# f29h85x_hsm_ctrl_regs register map
Vendor: Texas Instruments
Peripheral module from a debugger description file (folder HSM).
Registers are 32-bit, read-write, no defined reset value unless marked. A register's access mark holds for its fields unless they carry their own. Offsets are as the file gives them; lines under a group give offsets from that group; [hi:lo] are bit positions; {n}, {i} and the like mark numbered series; 'fields as' and 'values as' point back to an identical list; <NAME> marks a mode.

## HSM_CTRL — HSM CTRL Registers
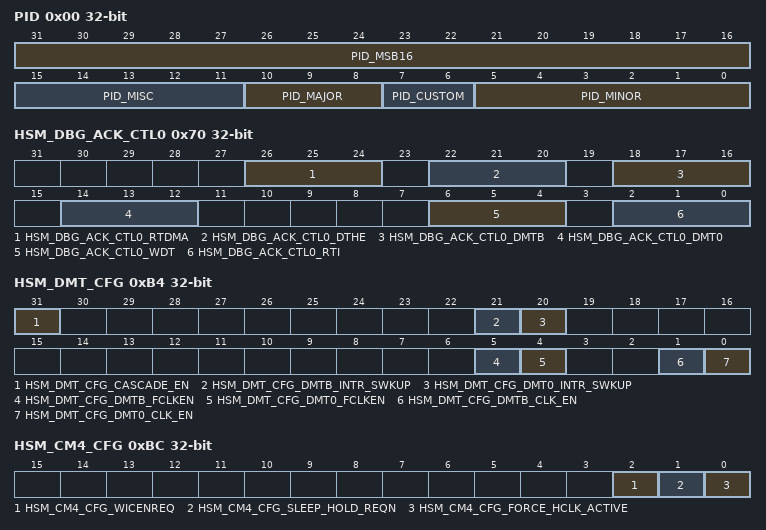
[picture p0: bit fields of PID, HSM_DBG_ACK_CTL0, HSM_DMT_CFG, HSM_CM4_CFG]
0x00 PID ro
  [31:16] PID_MSB16, [15:11] PID_MISC, [10:8] PID_MAJOR, [7:6] PID_CUSTOM, [5:0] PID_MINOR
{0x4+4i} HW_REG{i} (i=0..3)
  [31:0] HW_REG{i}_HWREG{i}
0x14 HSM_B0_MEMINIT_START
  [0] HSM_B0_MEMINIT_START_HSM_B0_MEMINIT_START
0x18 HSM_B0_MEMINIT_STATUS ro
  [0] HSM_B0_MEMINIT_STATUS_HSM_B0_MEMINIT_STATUS
0x1C HSM_B0_MEMINIT_DONE
  [0] HSM_B0_MEMINIT_DONE_HSM_B0_MEMINIT_DONE
0x20 HSM_B1_MEMINIT_START
  [0] HSM_B1_MEMINIT_START_HSM_B1_MEMINIT_START
0x24 HSM_B1_MEMINIT_STATUS ro
  [0] HSM_B1_MEMINIT_STATUS_HSM_B1_MEMINIT_STATUS
0x28 HSM_B1_MEMINIT_DONE
  [0] HSM_B1_MEMINIT_DONE_HSM_B1_MEMINIT_DONE
0x44 HSM_SECURERAM_MEMINIT_START
  [0] HSM_SECURERAM_MEMINIT_START_HSM_SECURE_MEMINIT_START
0x48 HSM_SECURERAM_MEMINIT_STATUS ro
  [0] HSM_SECURERAM_MEMINIT_STATUS_HSM_SECURE_MEMINIT_STATUS
0x4C HSM_SECURERAM_MEMINIT_DONE
  [0] HSM_SECURERAM_MEMINIT_DONE_HSM_SECURE_MEMINIT_DONE
0x70 HSM_DBG_ACK_CTL0
  [26:24] HSM_DBG_ACK_CTL0_RTDMA, [22:20] HSM_DBG_ACK_CTL0_DTHE, [18:16] HSM_DBG_ACK_CTL0_DMTB, [14:12] HSM_DBG_ACK_CTL0_DMT0, [6:4] HSM_DBG_ACK_CTL0_WDT, [2:0] HSM_DBG_ACK_CTL0_RTI
0x74 HSM_CM4_POR_RST_CTRL — Reserved. Not supported in this version of HW
  [2:0] HSM_CM4_POR_RST_CTRL_ASSERT
0x78 HSM_CM4_SYS_RST_CTRL — Reserved. Not supported in this version of HW
  [2:0] HSM_CM4_SYS_RST_CTRL_ASSERT
0x7C HSM_RTC_RST_CTRL — Reset control for RTC. Reset on PORESETn only
  [2:0] HSM_RTC_RST_CTRL_ASSERT
0x80 HSM_RTI0_RST_CTRL
  [2:0] HSM_RTI0_RST_CTRL_ASSERT
0x84 HSM_WDT_RST_CTRL
  [2:0] HSM_WDT_RST_CTRL_ASSERT
0x88 HSM_DCCA_RST_CTRL
  [2:0] HSM_DCCA_RST_CTRL_ASSERT
0x8C HSM_ESM_RST_CTRL
  [2:0] HSM_ESM_RST_CTRL_ASSERT
0x90 HSM_DMT0_RST_CTRL
  [2:0] HSM_DMT0_RST_CTRL_ASSERT
0x94 HSM_DMT1_RST_CTRL
  [2:0] HSM_DMT1_RST_CTRL_ASSERT
0x98 HSM_DMA_RST_CTRL
  [2:0] HSM_DMA_RST_CTRL_ASSERT
0x9C HSM_INFRA_RST_CTRL
  [2:0] HSM_INFRA_RST_CTRL_ASSERT
0xA0 HSM_DTHE_RST_CTRL
  [2:0] HSM_DTHE_RST_CTRL_ASSERT
0xA4 HSM_SHA_RST_CTRL
  [2:0] HSM_SHA_RST_CTRL_ASSERT
0xA8 HSM_TRNG_RST_CTRL
  [2:0] HSM_TRNG_RST_CTRL_ASSERT
0xAC HSM_PKE4P2_RST_CTRL
  [2:0] HSM_PKE4P2_RST_CTRL_ASSERT
0xB0 HSM_AES_RST_CTRL
  [2:0] HSM_AES_RST_CTRL_ASSERT
0xB4 HSM_DMT_CFG
  [31] HSM_DMT_CFG_CASCADE_EN, [21] HSM_DMT_CFG_DMTB_INTR_SWKUP, [20] HSM_DMT_CFG_DMT0_INTR_SWKUP, [5] HSM_DMT_CFG_DMTB_FCLKEN, [4] HSM_DMT_CFG_DMT0_FCLKEN, [1] HSM_DMT_CFG_DMTB_CLK_EN, [0] HSM_DMT_CFG_DMT0_CLK_EN
0xBC HSM_CM4_CFG
  [2] HSM_CM4_CFG_WICENREQ, [1] HSM_CM4_CFG_SLEEP_HOLD_REQN, [0] HSM_CM4_CFG_FORCE_HCLK_ACTIVE
0xC0 HSM_CM4_RST_CAUSE_CLR
  [2:0] HSM_CM4_RST_CAUSE_CLR_CLEAR
0xC4 HSM_CM4_RST_CAUSE ro — HSM CM4 reset cuase register. Reset on PORESETn
  [7:0] HSM_CM4_RST_CAUSE_STATUS
0xCC HSM_CM4_BOOTROM_ENABLE_STATUS ro
  [0] HSM_CM4_BOOTROM_ENABLE_STATUS_INDICATOR
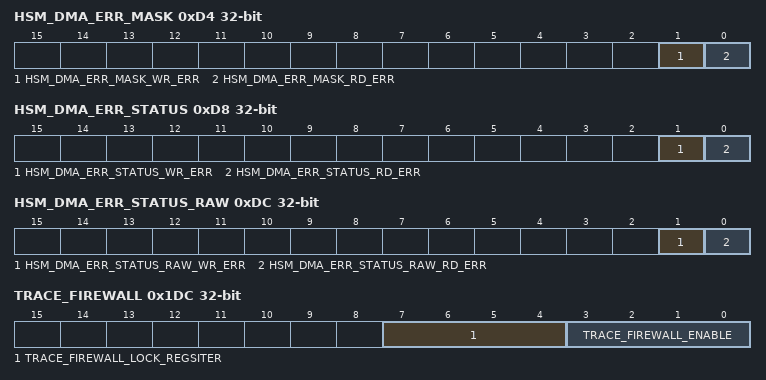
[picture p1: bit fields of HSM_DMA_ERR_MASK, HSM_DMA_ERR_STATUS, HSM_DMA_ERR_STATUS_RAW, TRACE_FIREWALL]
0xD4 HSM_DMA_ERR_MASK
  [1] HSM_DMA_ERR_MASK_WR_ERR, [0] HSM_DMA_ERR_MASK_RD_ERR
0xD8 HSM_DMA_ERR_STATUS
  [1] HSM_DMA_ERR_STATUS_WR_ERR, [0] HSM_DMA_ERR_STATUS_RD_ERR
0xDC HSM_DMA_ERR_STATUS_RAW
  [1] HSM_DMA_ERR_STATUS_RAW_WR_ERR, [0] HSM_DMA_ERR_STATUS_RAW_RD_ERR
0x1D0 DEVICE_TYPE ro
  [15:0] DEVICE_TYPE_DTYPE_RAW
0x1DC TRACE_FIREWALL
  [7:4] TRACE_FIREWALL_LOCK_REGSITER, [3:0] TRACE_FIREWALL_ENABLE
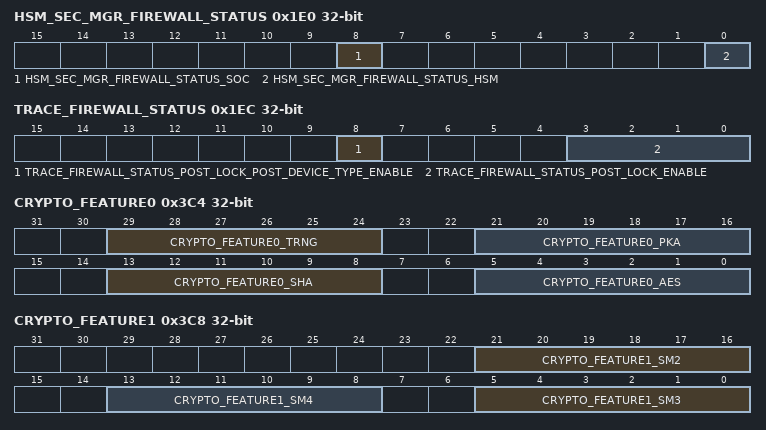
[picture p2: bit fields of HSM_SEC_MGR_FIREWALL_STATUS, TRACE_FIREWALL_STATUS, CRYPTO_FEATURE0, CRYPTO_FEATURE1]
0x1E0 HSM_SEC_MGR_FIREWALL_STATUS ro
  [8] HSM_SEC_MGR_FIREWALL_STATUS_SOC, [0] HSM_SEC_MGR_FIREWALL_STATUS_HSM
0x1EC TRACE_FIREWALL_STATUS ro
  [8] TRACE_FIREWALL_STATUS_POST_LOCK_POST_DEVICE_TYPE_ENABLE, [3:0] TRACE_FIREWALL_STATUS_POST_LOCK_ENABLE
0x200 HSM_SM3_RST_CTRL
  [2:0] HSM_SM3_RST_CTRL_ASSERT
0x204 HSM_SM4_RST_CTRL
  [2:0] HSM_SM4_RST_CTRL_ASSERT
0x208 HSM_XRSN_RST_CTRL — Control to generate XRSn on HSM output.
  [2:0] HSM_XRSN_RST_CTRL_ASSERT
0x20C HOST_CPU1_RST_CTRL — Control to generate SOC CPU1. This gets asserted conditionally when HSM CM4 is asserted. Once asserted, ROM code need to clear the field to get this reset deasserted.
  [2:0] HOST_CPU1_RST_CTRL_ASSERT
0x210 HOST_CPU2_RST_CTRL — Control to generate SOC CPU2. This gets asserted conditionally when HSM CM4 is asserted. Once asserted, ROM code need to clear the field to get this reset deasserted
  [2:0] HOST_CPU2_RST_CTRL_ASSERT
0x214 HOST_CPU3_RST_CTRL — Control to generate SOC CPU2. This gets asserted conditionally when HSM CM4 is asserted. Once asserted, ROM code need to clear the field to get this reset deasserted
  [2:0] HOST_CPU3_RST_CTRL_ASSERT
{0x208+4i} HOST_CPU{i}_RST_CTRL (i=4..6) — Control to generate SOC CPU{i}. This gets asserted conditionally when HSM CM4 is asserted. Once asserted, ROM code need to clear the field to get this reset deasserted
  [2:0] HOST_CPU{i}_RST_CTRL_ASSERT
0x228 HOST_CPU_M4RST_ENABLE_CTRL — Reserved. Not used in this version of HW
  [2:0] HOST_CPU_M4RST_ENABLE_CTRL_ENABLE
0x3A0 CPU0_BANKMAP — Active Bank Configuration for HSM CPU
  [7:0] CPU0_BANKMAP_SWAP
0x3B4 SWRV_FLW_ALLOWED0 — Allowed Software revisions for Flash Writer. Gets Reset on PORESETn. Write once until next PORESETn
  [31:0] SWRV_FLW_ALLOWED0_VALUE
0x3B8 SWRV_FLW_ALLOWED1 — Allowed Software revisions for Flash Writer. Gets Reset on PORESETn. Write once until next PORESETn
  [31:0] SWRV_FLW_ALLOWED1_VALUE
0x3BC UCID0 — UCID Value. Gets Reset on PORESETn. Write once until next PORESETn
  [31:0] UCID0_VALUE
0x3C0 UCID1 — UCID Value. Gets Reset on PORESETn. Write once until next PORESETn
  [31:0] UCID1_VALUE
0x3C4 CRYPTO_FEATURE0 ro — Indicate the availability of crypto features
  [29:24] CRYPTO_FEATURE0_TRNG, [21:16] CRYPTO_FEATURE0_PKA, [13:8] CRYPTO_FEATURE0_SHA, [5:0] CRYPTO_FEATURE0_AES
0x3C8 CRYPTO_FEATURE1 ro — Indicate the availability of crypto features
  [21:16] CRYPTO_FEATURE1_SM2, [13:8] CRYPTO_FEATURE1_SM4, [5:0] CRYPTO_FEATURE1_SM3
0x400 DMT0CLKSRCSEL — Clock source select configuration
  [2:0] DMT0CLKSRCSEL_SRC
0x404 DMTBCLKSRCSEL — Clock source select configuration
  [2:0] DMTBCLKSRCSEL_SRC
0x408 WDTACLKSRCSEL — Clock source select configuration
  [2:0] WDTACLKSRCSEL_SRC
0x40C RTIACLKSRCSEL — Clock source select configuration
  [2:0] RTIACLKSRCSEL_SRC
0x410 RTCCLKSRCSEL — Clock source select configuration. Reset on POR only
  [2:0] RTCCLKSRCSEL_SRC
0x1008 LOCK0_KICK0 — Lock register for HSM_SOC_CTRL registers.
0x100C LOCK0_KICK1 — Unlock register for HSM_SOC_CTRL registers.
